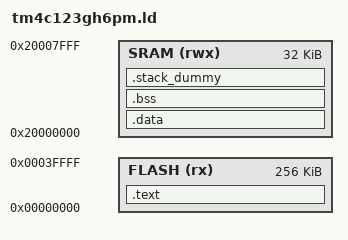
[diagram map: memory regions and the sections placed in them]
/**
 * tm4c123gh6pm.ld
 * Linker script for application. Mostly based on gcc_arm.ld file from CMSIS 5.
 * Author: akowalew
 */

ENTRY(resetISR)

/* Specify the memory areas */
MEMORY
{
    FLASH (rx) : ORIGIN = 0x00000000, LENGTH = 256K
    SRAM (rwx) : ORIGIN = 0x20000000, LENGTH = 32K
}

SECTIONS {
    .text :
    {
        KEEP(*(.stack_start_value)) /* Begin value for stack pointer */
        KEEP(*(.vectors)) /* Startup code */
        *(.text*)
        *(.rodata*)

        KEEP(*(.init))
        KEEP(*(.fini))

        /* .ctors */
        *crtbegin.o(.ctors)
        *crtbegin?.o(.ctors)
        *(EXCLUDE_FILE(*crtend?.o *crtend.o) .ctors)
        *(SORT(.ctors.*))
        *(.ctors)

        /* .dtors */
        *crtbegin.o(.dtors)
        *crtbegin?.o(.dtors)
        *(EXCLUDE_FILE(*crtend?.o *crtend.o) .dtors)
        *(SORT(.dtors.*))
        *(.dtors)

        *(.rodata*)

        KEEP(*(.eh_frame*))
    } >FLASH

    __etext = .;

    .data : AT (__etext)
    {
        __data_start__ = .;
        *(vtable)
        *(.data*)

        . = ALIGN(4);
        /* preinit data */
        PROVIDE_HIDDEN (__preinit_array_start = .);
        KEEP(*(.preinit_array))
        PROVIDE_HIDDEN (__preinit_array_end = .);

        . = ALIGN(4);
        /* init data */
        PROVIDE_HIDDEN (__init_array_start = .);
        KEEP(*(SORT(.init_array.*)))
        KEEP(*(.init_array))
        PROVIDE_HIDDEN (__init_array_end = .);


        . = ALIGN(4);
        /* finit data */
        PROVIDE_HIDDEN (__fini_array_start = .);
        KEEP(*(SORT(.fini_array.*)))
        KEEP(*(.fini_array))
        PROVIDE_HIDDEN (__fini_array_end = .);

        KEEP(*(.jcr*))
        . = ALIGN(4);

        /* All data end */
        __data_end__ = .;
    } >SRAM

    .bss :
    {
         . = ALIGN(4);
        __bss_start__ = .;
        *(.bss*)
        *(COMMON)
        . = ALIGN(4);
        __bss_end__ = .;
    } >SRAM

    /* .stack_dummy section doesn't contains any symbols. It is only
     * used for linker to calculate size of stack sections, and assign
     * values to stack symbols later */
    .stack_dummy (COPY):
    {
        KEEP(*(.stack*))
    } >SRAM

    /* Set stack top to end of SRAM, and stack limit move down by
     * size of stack_dummy section */
    _start_stack = ORIGIN(SRAM) + LENGTH(SRAM);
    _size_stack = _start_stack - SIZEOF(.stack_dummy);
    PROVIDE(__stack = _start_stack);
}
